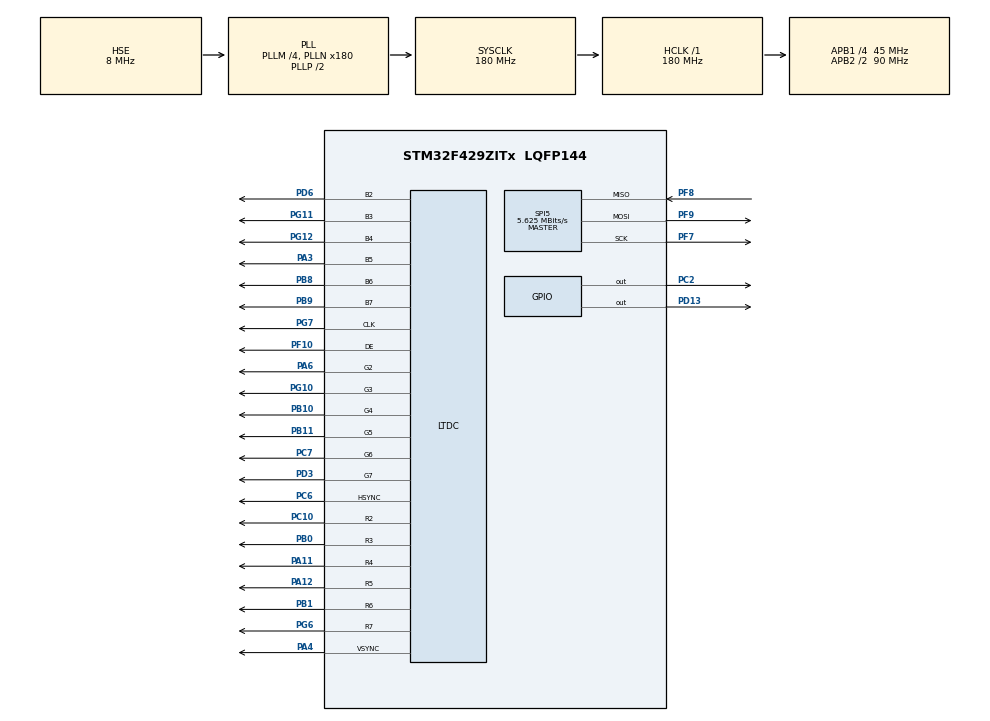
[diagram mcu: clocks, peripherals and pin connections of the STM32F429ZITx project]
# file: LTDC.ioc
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LTDC.ActiveH=320
LTDC.ActiveW=240
LTDC.Alpha_L0=255
LTDC.HBP=20
LTDC.HFP=10
LTDC.HSync=10
LTDC.ImageHeight_L0=320
LTDC.ImageWidth_L0=240
LTDC.Layers=0
LTDC.PixelFormat_L0=LTDC_PIXEL_FORMAT_RGB565
LTDC.VFP=4
LTDC.VSync=2
LTDC.WindowX1_L0=240
LTDC.WindowY1_L0=320
Mcu.Family=STM32F4
Mcu.Name=STM32F429ZITx
Mcu.Package=LQFP144
NVIC.PriorityGroup=NVIC_PRIORITYGROUP_4
PA11.Mode=RGB666
PA11.Signal=LTDC_R4
PA12.Mode=RGB666
PA12.Signal=LTDC_R5
PA3.Mode=RGB666
PA3.Signal=LTDC_B5
PA4.Mode=RGB666
PA4.Signal=LTDC_VSYNC
PA6.Mode=RGB666
PA6.Signal=LTDC_G2
PB0.Mode=RGB666
PB0.Signal=LTDC_R3
PB1.Mode=RGB666
PB1.Signal=LTDC_R6
PB10.Mode=RGB666
PB10.Signal=LTDC_G4
PB11.Mode=RGB666
PB11.Signal=LTDC_G5
PB8.Mode=RGB666
PB8.Signal=LTDC_B6
PB9.Mode=RGB666
PB9.Signal=LTDC_B7
PC10.Mode=RGB666
PC10.Signal=LTDC_R2
PC2.Signal=GPIO_Output
PC6.Mode=RGB666
PC6.Signal=LTDC_HSYNC
PC7.Mode=RGB666
PC7.Signal=LTDC_G6
PD13.Signal=GPIO_Output
PD3.Mode=RGB666
PD3.Signal=LTDC_G7
PD6.Mode=RGB666
PD6.Signal=LTDC_B2
PF10.Mode=RGB666
PF10.Signal=LTDC_DE
PF7.Mode=Full_Duplex_Master
PF7.Signal=SPI5_SCK
PF8.Mode=Full_Duplex_Master
PF8.Signal=SPI5_MISO
PF9.Mode=Full_Duplex_Master
PF9.Signal=SPI5_MOSI
PG10.Mode=RGB666
PG10.Signal=LTDC_G3
PG11.Mode=RGB666
PG11.Signal=LTDC_B3
PG12.Mode=RGB666
PG12.Signal=LTDC_B4
PG6.Mode=RGB666
PG6.Signal=LTDC_R7
PG7.Mode=RGB666
PG7.Signal=LTDC_CLK
PH0/OSC_IN.Mode=HSE-External-Oscillator
PH0/OSC_IN.Signal=RCC_OSC_IN
PH1/OSC_OUT.Mode=HSE-External-Oscillator
PH1/OSC_OUT.Signal=RCC_OSC_OUT
ProjectManager.HeapSize=0x200
ProjectManager.StackSize=0x400
ProjectManager.TargetToolchain=TrueSTUDIO
RCC.48MHZClocksFreq_Value=90000000
RCC.AHBFreq_Value=180000000
RCC.APB1CLKDivider=RCC_HCLK_DIV4
RCC.APB1Freq_Value=45000000
RCC.APB1TimFreq_Value=90000000
RCC.APB2CLKDivider=RCC_HCLK_DIV2
RCC.APB2Freq_Value=90000000
RCC.APB2TimFreq_Value=180000000
RCC.CortexFreq_Value=180000000
RCC.HCLKFreq_Value=180000000
RCC.HSE_VALUE=8000000
RCC.HSI_VALUE=16000000
RCC.LSE_VALUE=32768
RCC.PLLM=4
RCC.PLLN=180
RCC.PLLSAIDivR=RCC_PLLSAIDIVR_8
RCC.PLLSAIN=127
RCC.PLLSAIR=5
RCC.PLLSourceVirtual=RCC_PLLSOURCE_HSE
RCC.SYSCLKFreq_VALUE=180000000
RCC.SYSCLKSource=RCC_SYSCLKSOURCE_PLLCLK
RCC.VCOOutputFreq_Value=360000000
SPI5.BaudRatePrescaler=SPI_BAUDRATEPRESCALER_16
SPI5.CalculateBaudRate=5.625 MBits/s
SPI5.Direction=SPI_DIRECTION_2LINES
SPI5.Mode=SPI_MODE_MASTER
SPI5.VirtualType=VM_MASTER
board=custom

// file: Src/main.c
/* USER CODE BEGIN Header */
/**
  ******************************************************************************
  * @file           : main.c
  * @brief          : Main program body
  ******************************************************************************
  * @attention
  *
  * <h2><center>&copy; Copyright (c) 2019 STMicroelectronics.
  * All rights reserved.</center></h2>
  *
  * This software component is licensed by ST under BSD 3-Clause license,
  * the "License"; You may not use this file except in compliance with the
  * License. You may obtain a copy of the License at:
  *                        opensource.org/licenses/BSD-3-Clause
  *
  ******************************************************************************
  */
/* USER CODE END Header */

#include "main.h"

/* USER CODE BEGIN Includes */
#include "lcd_ili9341.h"
/* USER CODE END Includes */

LTDC_HandleTypeDef hltdc;

SPI_HandleTypeDef hspi5;

void SystemClock_Config(void);
static void MX_GPIO_Init(void);
static void MX_LTDC_Init(void);
static void MX_SPI5_Init(void);

/* USER CODE BEGIN 0 */
#define LCD_FRAME_BUFFER_SIZE (LCD_PIXEL_WIDTH*LCD_PIXEL_HEIGHT)

uint16_t u16arrFrameBuffer[LCD_FRAME_BUFFER_SIZE];
uint16_t *pFrameBuffer = u16arrFrameBuffer;
/* USER CODE END 0 */

int main(void)
{

  /* MCU Configuration--------------------------------------------------------*/

  /* Reset of all peripherals, Initializes the Flash interface and the Systick. */
  HAL_Init();

  /* Configure the system clock */
  SystemClock_Config();

  /* Initialize all configured peripherals */
  MX_GPIO_Init();
  MX_LTDC_Init();
  MX_SPI5_Init();
  /* USER CODE BEGIN 2 */
  LCD_PowerOn();
  HAL_LTDC_SetAddress(&hltdc, (uint32_t)pFrameBuffer, LTDC_LAYER_1);
  /* USER CODE END 2 */

  /* Infinite loop */
  while (1)
  {

    /* USER CODE BEGIN 3 */

  	for(int i=0; i<LCD_FRAME_BUFFER_SIZE; i++)
  	{
  		pFrameBuffer[i] = LCD_COLOR_RED;
  	}
  	HAL_Delay(1000);

  	for(int i=0; i<LCD_FRAME_BUFFER_SIZE; i++)
		{
			pFrameBuffer[i] = LCD_COLOR_BLUE;
		}
  	HAL_Delay(1000);
  }
  /* USER CODE END 3 */
}

void SystemClock_Config(void)
{
  RCC_OscInitTypeDef RCC_OscInitStruct = {0};
  RCC_ClkInitTypeDef RCC_ClkInitStruct = {0};
  RCC_PeriphCLKInitTypeDef PeriphClkInitStruct = {0};

  /** Configure the main internal regulator output voltage
  */
  __HAL_RCC_PWR_CLK_ENABLE();
  __HAL_PWR_VOLTAGESCALING_CONFIG(PWR_REGULATOR_VOLTAGE_SCALE1);
  /** Initializes the CPU, AHB and APB busses clocks
  */
  RCC_OscInitStruct.OscillatorType = RCC_OSCILLATORTYPE_HSE;
  RCC_OscInitStruct.HSEState = RCC_HSE_ON;
  RCC_OscInitStruct.PLL.PLLState = RCC_PLL_ON;
  RCC_OscInitStruct.PLL.PLLSource = RCC_PLLSOURCE_HSE;
  RCC_OscInitStruct.PLL.PLLM = 4;
  RCC_OscInitStruct.PLL.PLLN = 180;
  RCC_OscInitStruct.PLL.PLLP = RCC_PLLP_DIV2;
  RCC_OscInitStruct.PLL.PLLQ = 4;
  if (HAL_RCC_OscConfig(&RCC_OscInitStruct) != HAL_OK)
  {
    Error_Handler();
  }
  /** Activate the Over-Drive mode
  */
  if (HAL_PWREx_EnableOverDrive() != HAL_OK)
  {
    Error_Handler();
  }
  /** Initializes the CPU, AHB and APB busses clocks
  */
  RCC_ClkInitStruct.ClockType = RCC_CLOCKTYPE_HCLK|RCC_CLOCKTYPE_SYSCLK
                              |RCC_CLOCKTYPE_PCLK1|RCC_CLOCKTYPE_PCLK2;
  RCC_ClkInitStruct.SYSCLKSource = RCC_SYSCLKSOURCE_PLLCLK;
  RCC_ClkInitStruct.AHBCLKDivider = RCC_SYSCLK_DIV1;
  RCC_ClkInitStruct.APB1CLKDivider = RCC_HCLK_DIV4;
  RCC_ClkInitStruct.APB2CLKDivider = RCC_HCLK_DIV2;

  if (HAL_RCC_ClockConfig(&RCC_ClkInitStruct, FLASH_LATENCY_5) != HAL_OK)
  {
    Error_Handler();
  }
  PeriphClkInitStruct.PeriphClockSelection = RCC_PERIPHCLK_LTDC;
  PeriphClkInitStruct.PLLSAI.PLLSAIN = 127;
  PeriphClkInitStruct.PLLSAI.PLLSAIR = 5;
  PeriphClkInitStruct.PLLSAIDivR = RCC_PLLSAIDIVR_8;
  if (HAL_RCCEx_PeriphCLKConfig(&PeriphClkInitStruct) != HAL_OK)
  {
    Error_Handler();
  }
}

static void MX_LTDC_Init(void)
{

  LTDC_LayerCfgTypeDef pLayerCfg = {0};

  hltdc.Instance = LTDC;
  hltdc.Init.HSPolarity = LTDC_HSPOLARITY_AL;
  hltdc.Init.VSPolarity = LTDC_VSPOLARITY_AL;
  hltdc.Init.DEPolarity = LTDC_DEPOLARITY_AL;
  hltdc.Init.PCPolarity = LTDC_PCPOLARITY_IPC;
  hltdc.Init.HorizontalSync = 9;
  hltdc.Init.VerticalSync = 1;
  hltdc.Init.AccumulatedHBP = 29;
  hltdc.Init.AccumulatedVBP = 3;
  hltdc.Init.AccumulatedActiveW = 269;
  hltdc.Init.AccumulatedActiveH = 323;
  hltdc.Init.TotalWidth = 279;
  hltdc.Init.TotalHeigh = 327;
  hltdc.Init.Backcolor.Blue = 0;
  hltdc.Init.Backcolor.Green = 0;
  hltdc.Init.Backcolor.Red = 0;
  if (HAL_LTDC_Init(&hltdc) != HAL_OK)
  {
    Error_Handler();
  }
  pLayerCfg.WindowX0 = 0;
  pLayerCfg.WindowX1 = 240;
  pLayerCfg.WindowY0 = 0;
  pLayerCfg.WindowY1 = 320;
  pLayerCfg.PixelFormat = LTDC_PIXEL_FORMAT_RGB565;
  pLayerCfg.Alpha = 255;
  pLayerCfg.Alpha0 = 0;
  pLayerCfg.BlendingFactor1 = LTDC_BLENDING_FACTOR1_CA;
  pLayerCfg.BlendingFactor2 = LTDC_BLENDING_FACTOR2_CA;
  pLayerCfg.FBStartAdress = 0;
  pLayerCfg.ImageWidth = 240;
  pLayerCfg.ImageHeight = 320;
  pLayerCfg.Backcolor.Blue = 0;
  pLayerCfg.Backcolor.Green = 0;
  pLayerCfg.Backcolor.Red = 0;
  if (HAL_LTDC_ConfigLayer(&hltdc, &pLayerCfg, 0) != HAL_OK)
  {
    Error_Handler();
  }

}

static void MX_SPI5_Init(void)
{

  /* SPI5 parameter configuration*/
  hspi5.Instance = SPI5;
  hspi5.Init.Mode = SPI_MODE_MASTER;
  hspi5.Init.Direction = SPI_DIRECTION_2LINES;
  hspi5.Init.DataSize = SPI_DATASIZE_8BIT;
  hspi5.Init.CLKPolarity = SPI_POLARITY_LOW;
  hspi5.Init.CLKPhase = SPI_PHASE_1EDGE;
  hspi5.Init.NSS = SPI_NSS_SOFT;
  hspi5.Init.BaudRatePrescaler = SPI_BAUDRATEPRESCALER_16;
  hspi5.Init.FirstBit = SPI_FIRSTBIT_MSB;
  hspi5.Init.TIMode = SPI_TIMODE_DISABLE;
  hspi5.Init.CRCCalculation = SPI_CRCCALCULATION_DISABLE;
  hspi5.Init.CRCPolynomial = 10;
  if (HAL_SPI_Init(&hspi5) != HAL_OK)
  {
    Error_Handler();
  }

}

static void MX_GPIO_Init(void)
{
  GPIO_InitTypeDef GPIO_InitStruct = {0};

  /* GPIO Ports Clock Enable */
  __HAL_RCC_GPIOF_CLK_ENABLE();
  __HAL_RCC_GPIOH_CLK_ENABLE();
  __HAL_RCC_GPIOC_CLK_ENABLE();
  __HAL_RCC_GPIOA_CLK_ENABLE();
  __HAL_RCC_GPIOB_CLK_ENABLE();
  __HAL_RCC_GPIOD_CLK_ENABLE();
  __HAL_RCC_GPIOG_CLK_ENABLE();

  /*Configure GPIO pin Output Level */
  HAL_GPIO_WritePin(GPIOC, GPIO_PIN_2, GPIO_PIN_RESET);

  /*Configure GPIO pin Output Level */
  HAL_GPIO_WritePin(GPIOD, GPIO_PIN_13, GPIO_PIN_RESET);

  /*Configure GPIO pin : PC2 */
  GPIO_InitStruct.Pin = GPIO_PIN_2;
  GPIO_InitStruct.Mode = GPIO_MODE_OUTPUT_PP;
  GPIO_InitStruct.Pull = GPIO_NOPULL;
  GPIO_InitStruct.Speed = GPIO_SPEED_FREQ_LOW;
  HAL_GPIO_Init(GPIOC, &GPIO_InitStruct);

  /*Configure GPIO pin : PD13 */
  GPIO_InitStruct.Pin = GPIO_PIN_13;
  GPIO_InitStruct.Mode = GPIO_MODE_OUTPUT_PP;
  GPIO_InitStruct.Pull = GPIO_NOPULL;
  GPIO_InitStruct.Speed = GPIO_SPEED_FREQ_LOW;
  HAL_GPIO_Init(GPIOD, &GPIO_InitStruct);

}

void Error_Handler(void)
{
}

/************************ (C) COPYRIGHT STMicroelectronics *****END OF FILE****/
